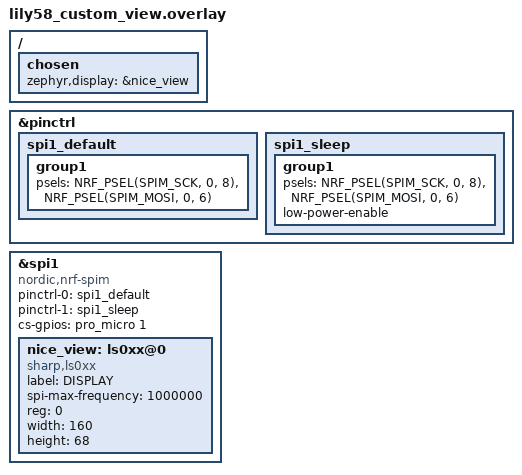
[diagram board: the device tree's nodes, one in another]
/*
 * Copyright (c) 2022 The ZMK Contributors
 *
 * SPDX-License-Identifier: MIT
 */

#include <dt-bindings/zmk/matrix_transform.h>

&pinctrl {
    spi1_default: spi1_default {
        group1 {
            psels = <NRF_PSEL(SPIM_SCK, 0, 8)>,
                    <NRF_PSEL(SPIM_MOSI, 0, 6)>;
        };
    };

    spi1_sleep: spi1_sleep {
        group1 {
            psels = <NRF_PSEL(SPIM_SCK, 0, 8)>,
                    <NRF_PSEL(SPIM_MOSI, 0, 6)>;
            low-power-enable;
        };
    };
};

&spi1 {
    compatible = "nordic,nrf-spim";
    status = "okay";
    pinctrl-0 = <&spi1_default>;
    pinctrl-1 = <&spi1_sleep>;
    pinctrl-names = "default", "sleep";
    cs-gpios = <&pro_micro 1 GPIO_ACTIVE_HIGH>;
    nice_view: ls0xx@0 {
        compatible = "sharp,ls0xx";
        label = "DISPLAY";
        spi-max-frequency = <1000000>;
        reg = <0>;
        width = <160>;
        height = <68>;
    };
};

/ {
    chosen {
        zephyr,display = &nice_view;
    };
};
